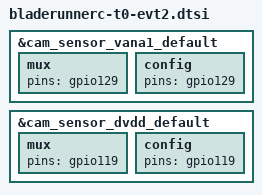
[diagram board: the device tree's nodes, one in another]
// kona-pinctrl.dtsi
&cam_sensor_vana1_default {
    /*  VIO LDO */
    mux {
        pins = "gpio129";
    };

    config {
        pins = "gpio129";
    };
};

&cam_sensor_dvdd_default {
    /*  VIO LDO */
    mux {
        pins = "gpio119";
    };

    config {
        pins = "gpio119";
    };
};
